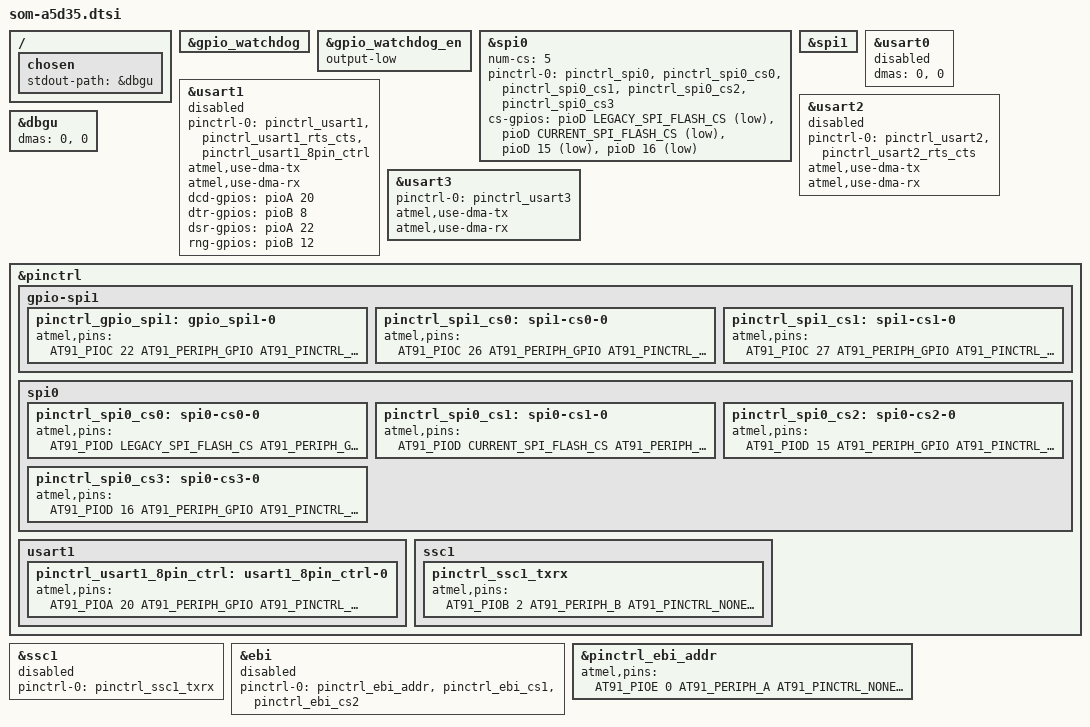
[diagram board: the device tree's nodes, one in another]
/*
 * som-a5d35.dtsi - Device Tree file for the SoM-A5D35.
 *
 *  Copyright (C) 2022 EMAC Inc.
 *
 * Licensed under GPLv2 or later.
 */

#include "som-a5d35-bare.dtsi"
#include <dt-bindings/gpio/gpio.h>

/ {
	chosen {
		stdout-path = &dbgu;
	};
};
// Enable Watchdog
&gpio_watchdog {
	status = "okay";
};
&gpio_watchdog_en {
	output-low;
	/* LOW - enabled , HIGH - disabled */
};

&spi0 {
	num-cs = <5>;
	pinctrl-0 = < &pinctrl_spi0
				  &pinctrl_spi0_cs0
				  &pinctrl_spi0_cs1
				  &pinctrl_spi0_cs2
				  &pinctrl_spi0_cs3
				>;
	cs-gpios = <&pioD LEGACY_SPI_FLASH_CS GPIO_ACTIVE_LOW>,
				<&pioD CURRENT_SPI_FLASH_CS GPIO_ACTIVE_LOW>,
				<&pioD 15 GPIO_ACTIVE_LOW>,
				<&pioD 16 GPIO_ACTIVE_LOW>;
};

&spi1 {
	// DO NOT USE WITH DMA
};

// COM A
&usart0 {
	dmas = <0>, <0>;	/*  Do not use DMA for usart0 */
	status = "disabled";
};

// COM C
&usart1 {
	pinctrl-names = "default";
	pinctrl-0 = <&pinctrl_usart1 &pinctrl_usart1_rts_cts &pinctrl_usart1_8pin_ctrl>;
	atmel,use-dma-tx;
	atmel,use-dma-rx;
	dcd-gpios = <&pioA 20 GPIO_ACTIVE_HIGH>;
	dtr-gpios = <&pioB 8 GPIO_ACTIVE_HIGH>;
	dsr-gpios = <&pioA 22 GPIO_ACTIVE_HIGH>;
	rng-gpios = <&pioB 12 GPIO_ACTIVE_HIGH>;
	status = "disabled";
};

// COM B
&usart2 {
	pinctrl-names = "default";
	pinctrl-0 = <&pinctrl_usart2 &pinctrl_usart2_rts_cts>;
	atmel,use-dma-tx;
	atmel,use-dma-rx;
	status = "disabled";
};

&usart3 {
	pinctrl-names = "default";
	pinctrl-0 = <&pinctrl_usart3>;
	atmel,use-dma-tx;
	atmel,use-dma-rx;
    status = "okay";
};

// COM E
&dbgu {
	dmas = <0>, <0>;	/*  Do not use DMA for dbgu */
	status = "okay";
};

&pinctrl {
	gpio-spi1 {
		pinctrl_gpio_spi1: gpio_spi1-0 {
			atmel,pins =
				<AT91_PIOC 22 AT91_PERIPH_GPIO AT91_PINCTRL_NONE
				 AT91_PIOC 23 AT91_PERIPH_GPIO AT91_PINCTRL_NONE
				 AT91_PIOC 24 AT91_PERIPH_GPIO AT91_PINCTRL_NONE>;
		};
		pinctrl_spi1_cs0: spi1-cs0-0 {
			atmel,pins =
				<AT91_PIOC 26 AT91_PERIPH_GPIO AT91_PINCTRL_NONE>;
		};
		pinctrl_spi1_cs1: spi1-cs1-0 {
			atmel,pins =
				<AT91_PIOC 27 AT91_PERIPH_GPIO AT91_PINCTRL_NONE>;
		};
	};

	spi0 {
		pinctrl_spi0_cs0: spi0-cs0-0 {
			atmel,pins =
				<AT91_PIOD LEGACY_SPI_FLASH_CS AT91_PERIPH_GPIO AT91_PINCTRL_NONE>;
		};

		pinctrl_spi0_cs1: spi0-cs1-0 {
			atmel,pins =
				<AT91_PIOD CURRENT_SPI_FLASH_CS AT91_PERIPH_GPIO AT91_PINCTRL_NONE>;
		};

		pinctrl_spi0_cs2: spi0-cs2-0 {
			atmel,pins =
				<AT91_PIOD 15 AT91_PERIPH_GPIO AT91_PINCTRL_NONE>;
		};

		pinctrl_spi0_cs3: spi0-cs3-0 {
			atmel,pins =
				<AT91_PIOD 16 AT91_PERIPH_GPIO AT91_PINCTRL_NONE>;
		};
	};
	usart1 {
		pinctrl_usart1_8pin_ctrl: usart1_8pin_ctrl-0 {
			atmel,pins =
				<AT91_PIOA 20 AT91_PERIPH_GPIO AT91_PINCTRL_NONE
				 AT91_PIOB 8 AT91_PERIPH_GPIO AT91_PINCTRL_NONE
				 AT91_PIOA 22 AT91_PERIPH_GPIO AT91_PINCTRL_NONE
				 AT91_PIOB 12 AT91_PERIPH_GPIO AT91_PINCTRL_NONE>;
		};
	};
	ssc1 {
		pinctrl_ssc1_txrx: pinctrl_ssc1_txrx {
			atmel,pins =
				<AT91_PIOB 2 AT91_PERIPH_B AT91_PINCTRL_NONE	/* PB2 periph B TK1 */
				 AT91_PIOB 3 AT91_PERIPH_B AT91_PINCTRL_NONE	/* PB3 periph B TF1 */
				 AT91_PIOB 6 AT91_PERIPH_B AT91_PINCTRL_NONE	/* PB6 periph B TD1 */
				 AT91_PIOB 10 AT91_PERIPH_B AT91_PINCTRL_NONE	/* PB10 periph B RD1 */
				 AT91_PIOB 11 AT91_PERIPH_B AT91_PINCTRL_NONE>;	/* PB11 periph B RF1 */
		};
	};
};

&ssc1 {
	pinctrl-names = "default";
	pinctrl-0 = <&pinctrl_ssc1_txrx>;
	status = "disabled";
};

&ebi {
	pinctrl-names = "default";
	pinctrl-0 = <&pinctrl_ebi_addr &pinctrl_ebi_cs1 &pinctrl_ebi_cs2>;
	status = "disabled";

	ranges = <0x1 0x0 0x40000000 0x10000000
			0x2 0x0 0x50000000 0x10000000
			0x3 0x0 0x60000000 0x10000000>;
};

&pinctrl_ebi_addr {
	atmel,pins =
		<AT91_PIOE 0 AT91_PERIPH_A AT91_PINCTRL_NONE
		 AT91_PIOE 1 AT91_PERIPH_A AT91_PINCTRL_NONE
		 AT91_PIOE 2 AT91_PERIPH_A AT91_PINCTRL_NONE
		 AT91_PIOE 3 AT91_PERIPH_A AT91_PINCTRL_NONE
		 AT91_PIOE 4 AT91_PERIPH_A AT91_PINCTRL_NONE
		 AT91_PIOE 5 AT91_PERIPH_A AT91_PINCTRL_NONE
		 AT91_PIOE 6 AT91_PERIPH_A AT91_PINCTRL_NONE
		 AT91_PIOE 7 AT91_PERIPH_A AT91_PINCTRL_NONE
		 AT91_PIOE 8 AT91_PERIPH_A AT91_PINCTRL_NONE
		 AT91_PIOE 9 AT91_PERIPH_A AT91_PINCTRL_NONE
		 AT91_PIOE 10 AT91_PERIPH_A AT91_PINCTRL_NONE
		 AT91_PIOE 11 AT91_PERIPH_A AT91_PINCTRL_NONE
		 AT91_PIOE 12 AT91_PERIPH_A AT91_PINCTRL_NONE
		 AT91_PIOE 13 AT91_PERIPH_A AT91_PINCTRL_NONE
		 AT91_PIOE 14 AT91_PERIPH_A AT91_PINCTRL_NONE
		 AT91_PIOE 15 AT91_PERIPH_A AT91_PINCTRL_NONE
		 AT91_PIOE 16 AT91_PERIPH_A AT91_PINCTRL_NONE
		 AT91_PIOE 17 AT91_PERIPH_A AT91_PINCTRL_NONE>;
};
